# ESP32S31_RADIO register map
Vendor: Espressif; Series: ESP32-S31; File version: 3.52
Registers are 32-bit, read-write, no defined reset value unless marked. A register's access mark holds for its fields unless they carry their own. Offsets are from the block's base; [hi:lo] are bit positions; {n}, {i} and the like mark numbered series; 'fields as' and 'values as' point back to an identical list.

## WIFI_MAC_AUX_TSF_CONTROL — SoftAP, NAN and broadcast-TWT TSF control words. Complete public leaves prove their addresses and exact enable/mode masks; unrelated bits and hardware transition rules remain unnamed.
Base 0x2010D860
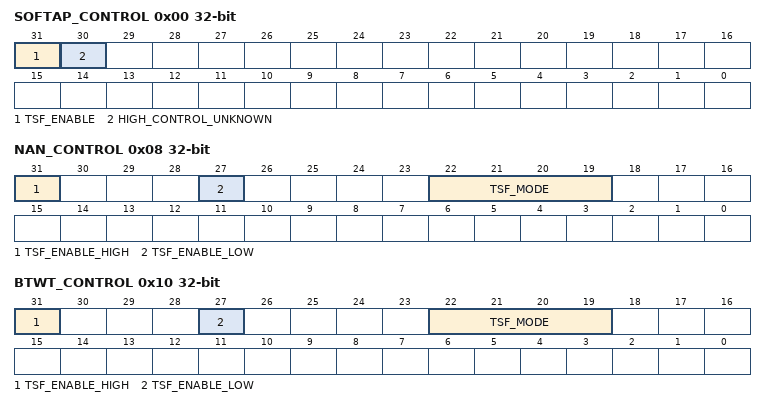
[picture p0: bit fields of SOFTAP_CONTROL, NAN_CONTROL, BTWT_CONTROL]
0x00 SOFTAP_CONTROL — Complete hal_disable_softap_tsf clears bits 31:30. Generic TSF enable/disable leaves independently identify bit 31 as the domain enable; bit 30 remains unknown.
  [31] TSF_ENABLE, [30] HIGH_CONTROL_UNKNOWN
0x08 NAN_CONTROL — Complete NAN enable/disable leaves use the same two-stage gate and mode transaction as station TSF at this distinct word.
  [31] TSF_ENABLE_HIGH, [27] TSF_ENABLE_LOW, [22:19] TSF_MODE
0x10 BTWT_CONTROL — Complete hal_enable_sta_btwt_tsf enables or disables the broadcast-TWT TSF domain using the same gate and mode masks as station TSF.
  [31] TSF_ENABLE_HIGH, [27] TSF_ENABLE_LOW, [22:19] TSF_MODE

## WIFI_MAC_TXRX_PREFIX — Eighteen direct fresh-read RMW edges before the first external HE callback in complete mac_txrx_init; complete hal_init later repeats the bit-28 set edge.
Base 0x201040FC
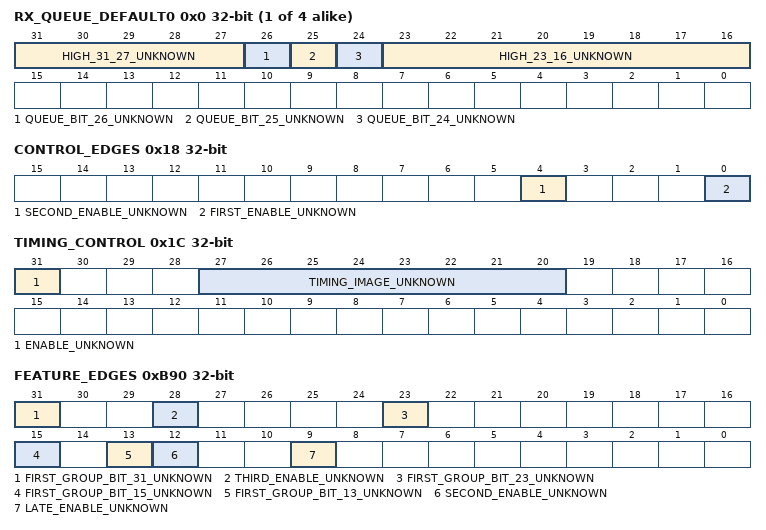
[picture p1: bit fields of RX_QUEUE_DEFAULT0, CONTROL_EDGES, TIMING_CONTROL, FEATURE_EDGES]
{0x0+4i} RX_QUEUE_DEFAULT{i} (i=0..3) — Four queue words have their high half cleared independently; queue zero and one then receive separate bit-24 and bit-26 set edges.
  [31:27] HIGH_31_27_UNKNOWN, [26] QUEUE_BIT_26_UNKNOWN, [25] QUEUE_BIT_25_UNKNOWN, [24] QUEUE_BIT_24_UNKNOWN, [23:16] HIGH_23_16_UNKNOWN
0x18 CONTROL_EDGES — Complete prefix sets bit 0, then bit 4 through a second fresh-read RMW.
  [4] SECOND_ENABLE_UNKNOWN, [0] FIRST_ENABLE_UNKNOWN
0x1C TIMING_CONTROL — Complete prefix sets bit 31, then replaces bits 27:20 with 0x1b in a separate RMW.
  [31] ENABLE_UNKNOWN, [27:20] TIMING_IMAGE_UNKNOWN
0xB90 FEATURE_EDGES — Four separately ordered prefix updates: first set bits 31,23,15,13 together; set bit 12; set bit 28; later set bit 9 after queue defaults. Complete hal_init repeats the bit-28 set after antenna initialization.
  [31] FIRST_GROUP_BIT_31_UNKNOWN
  [28] THIRD_ENABLE_UNKNOWN — Set once in mac_txrx_init and again at hal_init offset 0xe2 after the interrupt-mask store.
  [23] FIRST_GROUP_BIT_23_UNKNOWN
  [15] FIRST_GROUP_BIT_15_UNKNOWN
  [13] FIRST_GROUP_BIT_13_UNKNOWN
  [12] SECOND_ENABLE_UNKNOWN
  [9] LATE_ENABLE_UNKNOWN
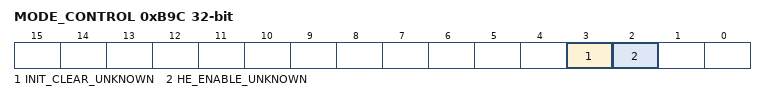
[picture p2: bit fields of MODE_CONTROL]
0xB9C MODE_CONTROL — Canonical multifunction word. Complete mac_txrx prefix clears bit 3; the HE init suffix independently sets bit 2.
  [3] INIT_CLEAR_UNKNOWN
  [2] HE_ENABLE_UNKNOWN — Complete HE init suffix sets bit 2.
0xBA4 SHARED_ENABLE_CONTROL — Final prefix RMW sets bits 1:0 together immediately before the first HE callback.
  [1:0] ENABLE_GROUP_UNKNOWN

## WIFI_MAC_TXRX_CALLBACKS — Hardware effects of the three HE callbacks between the direct mac_txrx_init prefix and suffix. Diagnostic logging calls are intentionally omitted.
Base 0x2010444C
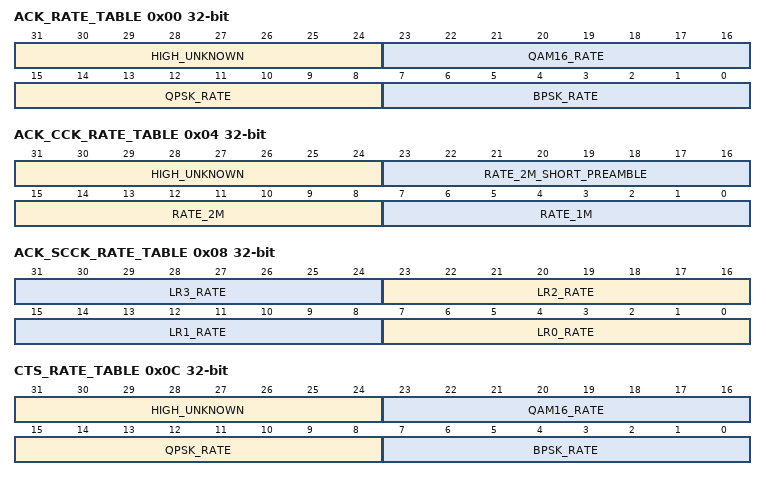
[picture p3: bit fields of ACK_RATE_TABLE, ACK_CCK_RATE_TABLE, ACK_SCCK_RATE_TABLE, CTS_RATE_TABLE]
0x00 ACK_RATE_TABLE — ACK_TAB0. hal_he_set_ack_rate(0) publishes 0x00090a0b; complete dbg_read_ack_rate names its three byte lanes.
  [31:24] HIGH_UNKNOWN, [23:16] QAM16_RATE, [15:8] QPSK_RATE, [7:0] BPSK_RATE
0x04 ACK_CCK_RATE_TABLE — ACK_TAB1. hal_he_set_ack_rate(0) publishes 0x00050100; complete dbg_read_ack_rate names the 1M, 2M and short-preamble 2M lanes.
  [31:24] HIGH_UNKNOWN, [23:16] RATE_2M_SHORT_PREAMBLE, [15:8] RATE_2M, [7:0] RATE_1M
0x08 ACK_SCCK_RATE_TABLE — ACK_SCCKTAB, decoded by complete dbg_read_ack_rate. The cold setter does not alter this word.
  [8n+7:8n] LR{n}_RATE (n=0..3)
0x0C CTS_RATE_TABLE — CTS_TAB0. hal_he_set_ack_rate(0) publishes 0x00090a0b; complete dbg_read_cts_rate names its three byte lanes.
  fields as ACK_RATE_TABLE
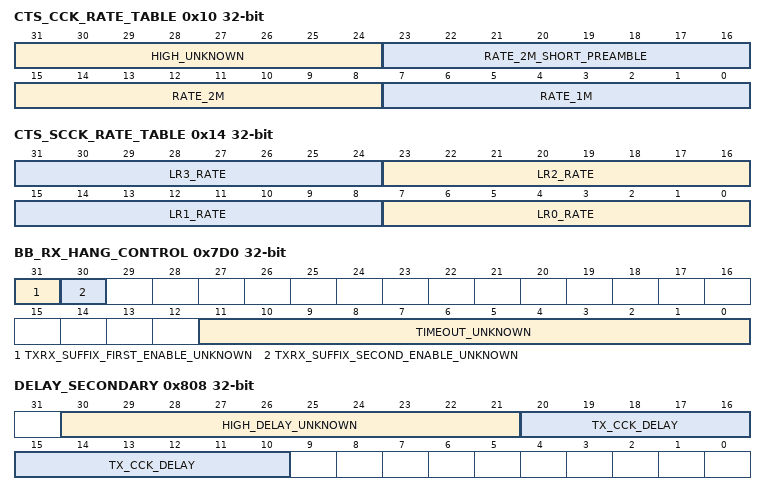
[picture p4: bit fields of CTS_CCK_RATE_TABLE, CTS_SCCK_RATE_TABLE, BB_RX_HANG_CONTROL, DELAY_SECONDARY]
0x10 CTS_CCK_RATE_TABLE — CTS_TAB1. hal_he_set_ack_rate(0) publishes 0x00050100; complete dbg_read_cts_rate names the 1M, 2M and short-preamble 2M lanes.
  fields as ACK_CCK_RATE_TABLE
0x14 CTS_SCCK_RATE_TABLE — CTS_SCCKTAB, decoded by complete dbg_read_cts_rate. The cold setter does not alter this word.
  [8n+7:8n] LR{n}_RATE (n=0..3)
0x7D0 BB_RX_HANG_CONTROL — Canonical multifunction word. hal_he_set_bbrxhung_time(0) replaces the low twelve bits with 0x00f; the direct mac_txrx_init suffix later sets bits 31 and 30 through two fresh-read RMWs.
  [31] TXRX_SUFFIX_FIRST_ENABLE_UNKNOWN, [30] TXRX_SUFFIX_SECOND_ENABLE_UNKNOWN, [11:0] TIMEOUT_UNKNOWN
0x808 DELAY_SECONDARY — WDEVDELAY1. On-chip hal_he_set_mac_delay uses random slot 0..10 for bits 30:21, while complete phy_sifs_reg_init writes 0xea to that field.
  [30:21] HIGH_DELAY_UNKNOWN, [20:10] TX_CCK_DELAY
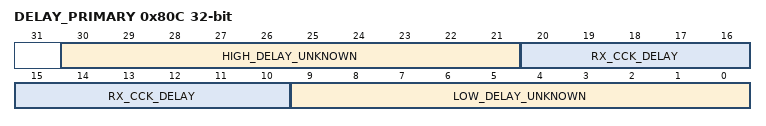
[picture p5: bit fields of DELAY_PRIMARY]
0x80C DELAY_PRIMARY — WDEVDELAY. On-chip hal_he_set_mac_delay performs separate RMWs for WDEV_RXCCK_DELAY, bits 9:0 and bits 30:21; complete phy_sifs_reg_init writes 0x3b8 and 0xf0 to the first two fields.
  [30:21] HIGH_DELAY_UNKNOWN, [20:10] RX_CCK_DELAY, [9:0] LOW_DELAY_UNKNOWN
